# SIMG301M104LIH register map
Vendor: Silicon Labs; Series: Si; File version: B
Registers are 32-bit, read-write, reset 0x0 unless marked. A register's access mark holds for its fields unless they carry their own. Offsets are from the block's base; [hi:lo] are bit positions; {n}, {i} and the like mark numbered series; 'fields as' and 'values as' point back to an identical list.

## LDMA0_NS — LDMA0_NS Registers
Base 0x40814000
Same registers: LDMA0_S 0x50814000
0x00 IPVERSION ro reset 0x3
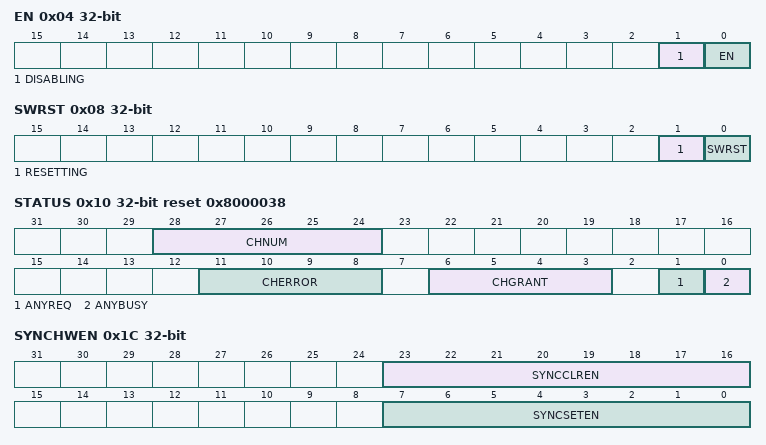
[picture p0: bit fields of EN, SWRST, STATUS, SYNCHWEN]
0x04 EN — Module enable disable Register
  [1] DISABLING ro — Disablement busy status
  [0] EN — Module Enable
0x08 SWRST — Software Reset Register
  [1] RESETTING ro — Software Reset Busy Status
  [0] SWRST wo — Software Reset Command
0x0C CTRL reset 0x1E000000 — Control Register
  [29:24] NUMFIXED — Number of Fixed Priority Channels
0x10 STATUS ro reset 0x8000038
  [28:24] CHNUM — Number of Channels
  [11:8] CHERROR — Errant Channel Number
  [6:3] CHGRANT — Granted Channel Number
  [1] ANYREQ — Any DMA Channel Request Pending
  [0] ANYBUSY — Any DMA Channel Busy
0x14 SYNCSWSET wo — Sync Trig Sw Set Register (Writes will only take effect when EN=1)
  [7:0] SYNCSWSET — DMA SYNC Software Trigger Set
0x18 SYNCSWCLR wo — Sync Trig Sw Clear register (Writes will only take effect when EN=1)
  [7:0] SYNCSWCLR — DMA SYNC Software Trigger Clear
0x1C SYNCHWEN — Sync HW trigger enable register
  [23:16] SYNCCLREN — Hardware Sync Trigger Clear Enable
  [7:0] SYNCSETEN — Hardware Sync Trigger Set Enable
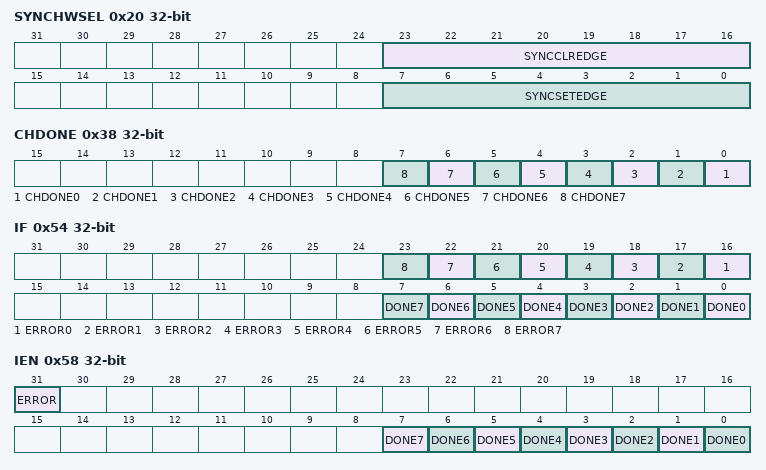
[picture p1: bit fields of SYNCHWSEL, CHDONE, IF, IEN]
0x20 SYNCHWSEL — Sync HW trigger selection register
  [23:16] SYNCCLREDGE — Hardware Sync Trigger Clear Edge Select
    0=RISE (Use rising edge detection); 1=FALL (Use falling edge detection)
  [7:0] SYNCSETEDGE — Hardware Sync Trigger Set Edge Select
    values as SYNCCLREDGE
0x24 SYNCSTATUS ro — Sync Trigger Status Register
  [7:0] SYNCTRIG — sync trig status
0x28 CHEN wo — Channel Enable Register (Writes will only take effect when EN=1)
  [7:0] CHEN — Channel Enables
0x2C CHDIS wo — Channel Disable Register (Writes will only take effect when EN=1)
  [7:0] CHDIS — DMA Channel disable
0x30 CHSTATUS ro — Channel Status Register
  [7:0] CHSTATUS — DMA Channel Status
0x34 CHBUSY ro — Channel Busy Register
  [7:0] BUSY — Channels Busy
0x38 CHDONE — Channel Linking Done Status Register (Writes will only take effect when EN=1)
  [n] CHDONE{n} (n=0..7) — Channel {n} Linking Done Status flag
0x3C DBGHALT — Channel Debug Halt Register
  [7:0] DBGHALT — DMA Debug Halt
0x40 SWREQ wo — Channel Software Transfer Request (Writes will only take effect when EN=1)
  [7:0] SWREQ — Software Transfer Requests
0x44 REQDIS — Channel Request Disable Register (Writes will only take effect when EN=1)
  [7:0] REQDIS — DMA Request Disables
0x48 REQPEND ro — Channel Requests Pending Register
  [7:0] REQPEND — DMA Requests Pending
0x4C LINKLOAD wo — Channel Link Load Register (Writes will only take effect when EN=1)
  [7:0] LINKLOAD — DMA Link Loads
0x50 REQCLEAR wo — Channel Request Clear Register (Writes will only take effect when EN=1)
  [7:0] REQCLEAR — DMA Request Clear
0x54 IF — Interrupt Flag Register (Writes will only take effect when EN=1)
  [n+16] ERROR{n} (n=0..7) — Error Flag
  [n] DONE{n} (n=0..7) — Done Interrupt Flag
0x58 IEN — Done Interrupt Enable Register
  [31] ERROR — Error Interrupt Enable
  [n] DONE{n} (n=0..7) — Done Interrupt Enable
0x5C REQABORT wo — DMA Req abort register (Writes will only take effect when EN=1)
  [7:0] REQABORT
0x60 ABORTSTATUS ro reset 0xFF — Req Abort status register
  [7:0] ABORTSTATUS — Req Abort Status bit
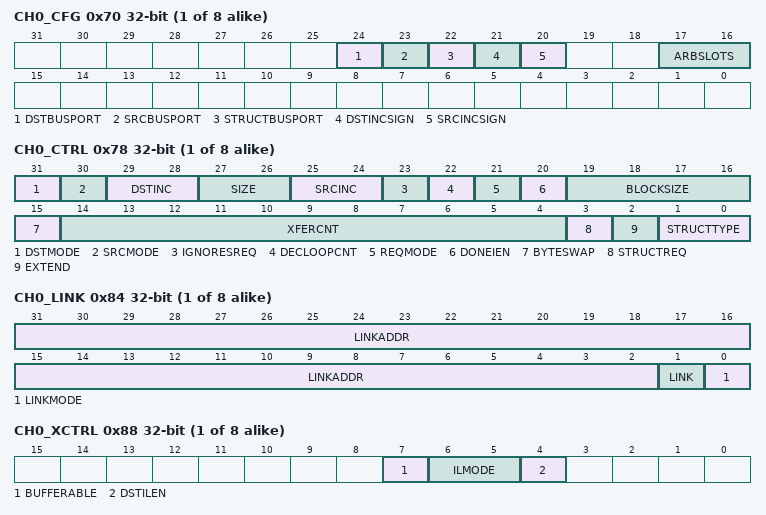
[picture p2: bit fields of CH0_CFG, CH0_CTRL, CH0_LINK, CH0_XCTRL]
{0x70+0x30*i} CH{i}_CFG (i=0..7) — Channel Configuration Register
  [24] DSTBUSPORT — Destination Bus Port
    0=AHBM0; 1=AHBM1
  [23] SRCBUSPORT — Source Bus Port
    0=AHBM0; 1=AHBM1
  [22] STRUCTBUSPORT — Structure Fetch Bus Port
    0=AHBM0; 1=AHBM1
  [21] DSTINCSIGN — Destination Address Increment Sign
    0=POSITIVE (Increment destination address); 1=NEGATIVE (Decrement destination address)
  [20] SRCINCSIGN — Source Address Increment Sign
    0=POSITIVE (Increment source address); 1=NEGATIVE (Decrement source address)
  [17:16] ARBSLOTS — Arbitration Slot Number Select
    0=ONE (One arbitration slot selected); 1=TWO (Two arbitration slots selected); 2=FOUR (Four arbitration slots selected); 3=EIGHT (Eight arbitration slots selected)
{0x74+0x30*i} CH{i}_LOOP (i=0..7) — Channel Loop Counter Register (Writes will only take effect when EN=1)
  [7:0] LOOPCNT — Linked Structure Sequence Loop Counter
{0x78+0x30*i} CH{i}_CTRL (i=0..7) — Channel Descriptor Control Word Register (Writes will only take effect when EN=1)
  [31] DSTMODE ro — Destination Addressing Mode
    0=ABSOLUTE (The DSTADDR field of LDMA_CHx_DST contains the absolute address of the destination data.); 1=RELATIVE (The DSTADDR field of LDMA_CHx_DST contains the relative offset of the destination data.)
  [30] SRCMODE ro — Source Addressing Mode
    0=ABSOLUTE (The SRCADDR field of LDMA_CHx_SRC contains the absolute address of the source data.); 1=RELATIVE (The SRCADDR field of LDMA_CHx_SRC contains the relative offset of the source data.)
  [29:28] DSTINC — Destination Address Increment Size
    0=ONE (Increment destination address by one unit data size after each write); 1=TWO (Increment destination address by two unit data sizes after each write); 2=FOUR (Increment destination address by four unit data sizes after each write); 3=NONE (Do not increment the destination address. Writes are made to a fixed destination address, for example writing to a FIFO.)
  [27:26] SIZE — Unit Data Transfer Size
    0=BYTE (Each unit transfer is a byte); 1=HALFWORD (Each unit transfer is a half-word); 2=WORD (Each unit transfer is a word)
  [25:24] SRCINC — Source Address Increment Size
    0=ONE (Increment source address by one unit data size after each read); 1=TWO (Increment source address by two unit data sizes after each read); 2=FOUR (Increment source address by four unit data sizes after each read); 3=NONE (Do not increment the source address. In this mode reads are made from a fixed source address, for example reading FIFO.)
  [23] IGNORESREQ
  [22] DECLOOPCNT — Decrement Loop Count
  [21] REQMODE — DMA Request Transfer Mode Select
    0=BLOCK (The LDMA transfers one BLOCKSIZE per transfer request.); 1=ALL (One transfer request transfers all units as defined by the XFRCNT field.)
  [20] DONEIEN — DMA Operation Done Interrupt Flag Set
  [19:16] BLOCKSIZE — Block Transfer Size
    0=UNIT1 (1 unit transfer per arbitration); 1=UNIT2 (2 unit transfers per arbitration); 2=UNIT3 (3 unit transfers per arbitration); 3=UNIT4 (4 unit transfers per arbitration); 4=UNIT6 (6 unit transfers per arbitration); 5=UNIT8 (8 unit transfers per arbitration); 6=UNIT12 (12 unit transfers per arbitration); 7=UNIT16 (16 unit transfers per arbitration); 8=UNIT24 (24 unit transfers per arbitration); 9=UNIT32 (32 unit transfers per arbitration); 10=UNIT64 (64 unit transfers per arbitration); 11=UNIT128 (128 unit transfers per arbitration); 12=UNIT256 (256 unit transfers per arbitration); 13=UNIT512 (512 unit transfers per arbitration); 14=UNIT1024 (1024 unit transfers per arbitration); 15=ALL (Transfer all units as specified by the XFRCNT field)
  [15] BYTESWAP — Endian Byte Swap
  [14:4] XFERCNT — DMA Unit Data Transfer Count
  [3] STRUCTREQ ro — Structure DMA Transfer Request
  [2] EXTEND
  [1:0] STRUCTTYPE — DMA Structure Type
    0=TRANSFER (DMA transfer structure type selected.); 1=SYNCHRONIZE (Synchronization structure type selected.); 2=WRITE (Write immediate value structure type selected.)
{0x7C+0x30*i} CH{i}_SRC (i=0..7) — Channel Descriptor Source Address Register (Writes will only take effect when EN=1)
  [31:0] ADDR — Source Data Address
{0x80+0x30*i} CH{i}_DST (i=0..7) — Channel Descriptor Destination Address Register (Writes will only take effect when EN=1)
  [31:0] ADDR — Destination Data Address
{0x84+0x30*i} CH{i}_LINK (i=0..7) — Channel Descriptor Link Address Register (Writes will only take effect when EN=1)
  [31:2] LINKADDR — Link Structure Address
  [1] LINK — Link Next Structure
  [0] LINKMODE ro — Link Structure Addressing Mode
    0=ABSOLUTE (The LINKADDR field of LDMA_CHx_LINK contains the absolute address of the linked descriptor.); 1=RELATIVE (The LINKADDR field of LDMA_CHx_LINK contains the relative offset of the linked descriptor.)
{0x88+0x30*i} CH{i}_XCTRL (i=0..7) — Channel Extended Descriptor Control Register (Writes will only take effect when EN=1)
  [7] BUFFERABLE — Allow AHB buffering
  [6:5] ILMODE — Interleave Mode
    0=ABSOLUTE (Address determined by value in rules. Size of WORD); 1=RELATIVE16 (Address determined by adding rules to DST. Size of HALFWORD); 2=RELATIVE8 (Address determined by adding rules to DST. Size of BYTE)
  [4] DSTILEN — Destination Interleave
{0x90+0x30*i} CH{i}_ILSRC (i=0..7) — Channel Extended Descriptor Interleaving Source Address Register (Writes will only take effect when EN=1)
  [31:0] ADDR — Interleave Source Address
